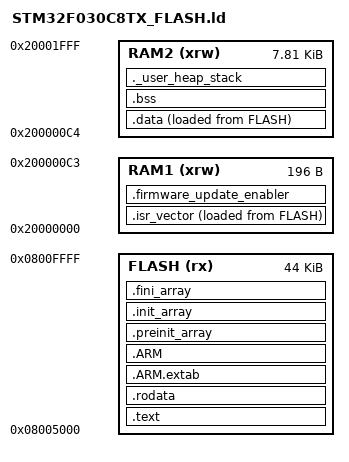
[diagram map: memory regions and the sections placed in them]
/*
******************************************************************************
**
** @file        : LinkerScript.ld
**
** @author      : Auto-generated by STM32CubeIDE
**
** @brief       : Linker script for STM32F030C8Tx Device from STM32F0 series
**                      64Kbytes FLASH
**                      8Kbytes RAM
**
**                Set heap size, stack size and stack location according
**                to application requirements.
**
**                Set memory bank area and size if external memory is used
**
**  Target      : STMicroelectronics STM32
**
**  Distribution: The file is distributed as is, without any warranty
**                of any kind.
**
******************************************************************************
** @attention
**
** Copyright (c) 2022 STMicroelectronics.
** All rights reserved.
**
** This software is licensed under terms that can be found in the LICENSE file
** in the root directory of this software component.
** If no LICENSE file comes with this software, it is provided AS-IS.
**
******************************************************************************
*/

/* Entry Point */
ENTRY(Reset_Handler)

/* Highest address of the user mode stack */
_estack = ORIGIN(RAM2) + LENGTH(RAM2); /* end of "RAM2" Ram type memory */

/* Bootloader flash pages */
_bootloader_pages = 64 - (LENGTH(FLASH) / 1024);

_Min_Heap_Size = 0x200 ; /* required amount of heap */
_Min_Stack_Size = 0xc00; /* required amount of stack */

/* Memories definition
 * RAM1: Shared with the bootloader at fixed addresses, must start at SRAM
 *       start. Cortex-M0 has no VTOR, the vector table is always read from
 *       address 0. The startup code copies .isr_vector (48 words) here and
 *       SystemInit() remaps SRAM to address 0. firmware_update_enabler follows
 *       at 0x200000C0, the bootloader reads it after reset.
 * RAM2: Application data, heap and stack. The bootloader uses the same RAM,
 *       it resets all peripherals and interrupts before jumping here, so none
 *       of its code runs after the jump.
 */
MEMORY
{
  RAM1    (xrw)    : ORIGIN = 0x20000000,   LENGTH = 196
  RAM2    (xrw)    : ORIGIN = 0x200000C4,   LENGTH = 7996
  FLASH    (rx)    : ORIGIN = 0x8005000,   LENGTH = 44K
}

/* Sections */
SECTIONS
{
  /* Used by the startup to initialize isr_vector */
  _siisr_vector = LOADADDR(.isr_vector);

  /* The startup code into "FLASH" Rom type memory */
  .isr_vector :
  {
    . = ALIGN(4);
    _sisr_vector = .;
    KEEP(*(.isr_vector)) /* Startup code */
    
    . = ALIGN(4);
    _eisr_vector = .;        /* define a global symbol at data end */
  } >RAM1 AT> FLASH
  
  /* Reserved RAM shared between APP and BOOT, NOLOAD: not zeroed by the
   * startup code. Its address is hard-coded in the bootloader's linker
   * script, so it must stay right after the vector table.
   */
  .firmware_update_enabler (NOLOAD) :
  {
    . = ALIGN(4);  
    KEEP(*(.firmware_update_enabler))
    . = ALIGN(4);
  } >RAM1

  /* The program code and other data into "FLASH" Rom type memory */
  .text :
  {
    . = ALIGN(4);
    *(.text)           /* .text sections (code) */
    *(.text*)          /* .text* sections (code) */
    *(.glue_7)         /* glue arm to thumb code */
    *(.glue_7t)        /* glue thumb to arm code */
    *(.eh_frame)

    KEEP (*(.init))
    KEEP (*(.fini))

    . = ALIGN(4);
    _etext = .;        /* define a global symbols at end of code */
  } >FLASH

  /* Constant data into "FLASH" Rom type memory */
  .rodata :
  {
    . = ALIGN(4);
    *(.rodata)         /* .rodata sections (constants, strings, etc.) */
    *(.rodata*)        /* .rodata* sections (constants, strings, etc.) */
    . = ALIGN(4);
  } >FLASH

  .ARM.extab   : {
    . = ALIGN(4);
    *(.ARM.extab* .gnu.linkonce.armextab.*)
    . = ALIGN(4);
  } >FLASH

  .ARM : {
    . = ALIGN(4);
    __exidx_start = .;
    *(.ARM.exidx*)
    __exidx_end = .;
    . = ALIGN(4);
  } >FLASH

  .preinit_array     :
  {
    . = ALIGN(4);
    PROVIDE_HIDDEN (__preinit_array_start = .);
    KEEP (*(.preinit_array*))
    PROVIDE_HIDDEN (__preinit_array_end = .);
    . = ALIGN(4);
  } >FLASH

  .init_array :
  {
    . = ALIGN(4);
    PROVIDE_HIDDEN (__init_array_start = .);
    KEEP (*(SORT(.init_array.*)))
    KEEP (*(.init_array*))
    PROVIDE_HIDDEN (__init_array_end = .);
    . = ALIGN(4);
  } >FLASH

  .fini_array :
  {
    . = ALIGN(4);
    PROVIDE_HIDDEN (__fini_array_start = .);
    KEEP (*(SORT(.fini_array.*)))
    KEEP (*(.fini_array*))
    PROVIDE_HIDDEN (__fini_array_end = .);
    . = ALIGN(4);
  } >FLASH

  /* Used by the startup to initialize data */
  _sidata = LOADADDR(.data);

  /* Initialized data sections into "RAM2" Ram type memory */
  .data :
  {
    . = ALIGN(4);
    _sdata = .;        /* create a global symbol at data start */
    *(.data)           /* .data sections */
    *(.data*)          /* .data* sections */
    *(.RamFunc)        /* .RamFunc sections */
    *(.RamFunc*)       /* .RamFunc* sections */

    . = ALIGN(4);
    _edata = .;        /* define a global symbol at data end */

  } >RAM2 AT> FLASH

  /* Uninitialized data section into "RAM2" Ram type memory */
  . = ALIGN(4);
  .bss :
  {
    /* This is used by the startup in order to initialize the .bss section */
    _sbss = .;         /* define a global symbol at bss start */
    __bss_start__ = _sbss;
    *(.bss)
    *(.bss*)
    *(COMMON)

    . = ALIGN(4);
    _ebss = .;         /* define a global symbol at bss end */
    __bss_end__ = _ebss;
  } >RAM2

  /* User_heap_stack section, used to check that there is enough "RAM2" Ram  type memory left */
  ._user_heap_stack :
  {
    . = ALIGN(8);
    PROVIDE ( end = . );
    PROVIDE ( _end = . );
    . = . + _Min_Heap_Size;
    . = . + _Min_Stack_Size;
    . = ALIGN(8);
  } >RAM2

  /* Remove information from the compiler libraries */
  /DISCARD/ :
  {
    libc.a ( * )
    libm.a ( * )
    libgcc.a ( * )
  }

  .ARM.attributes 0 : { *(.ARM.attributes) }

  /* Main program flash size, the initial values of .data are the last in
   * FLASH. Outside of an output section, so the addresses are absolute.
   */
  _main_program_size = LOADADDR(.data) + SIZEOF(.data) - ORIGIN(FLASH);

  /* Bootloader flash size */
  _bootloader_size = ORIGIN(FLASH) - 0x8000000;

  ASSERT(ADDR(.firmware_update_enabler) == 0x200000C0,
         "firmware_update_enabler moved, the bootloader reads 0x200000C0")
  /* Must match the bootloader's FLASH end (bootloader Release) */
  ASSERT(ORIGIN(FLASH) == 0x8005000,
         "Application start changed: update LENGTH(FLASH) in mueb4-firmware-boot/STM32F030C8TX_FLASH.ld and this ASSERT")
}
